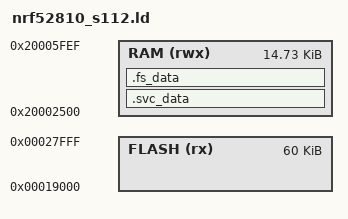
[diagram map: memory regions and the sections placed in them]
/* Linker script to configure memory regions. */

SEARCH_DIR(.)
GROUP(-lgcc -lc -lnosys)

MEMORY
{
  FLASH (rx) : ORIGIN = 0x00019000, LENGTH = 0x00028000 - 0x00019000
  RAM (rwx) :  ORIGIN = 0x20002500, LENGTH = 0x3AF0
}

SECTIONS
{
  . = ALIGN(4);
  .svc_data :
  {
    PROVIDE(__start_svc_data = .);
    KEEP(*(.svc_data))
    PROVIDE(__stop_svc_data = .);
  } > RAM
  
  .fs_data :
  {
    PROVIDE(__start_fs_data = .);
    KEEP(*(.fs_data))
    PROVIDE(__stop_fs_data = .);
  } > RAM
} INSERT AFTER .data;


INCLUDE "nrf_common.ld"
